# D1H register map
Vendor: Allwinner; File version: 1.0
Registers are 32-bit, read-write, reset 0x0 unless marked. A register's access mark holds for its fields unless they carry their own. Offsets are from the block's base; [hi:lo] are bit positions; {n}, {i} and the like mark numbered series.

## CIR_RX — Counsumer Infrared Receiver
Base 0x07040000
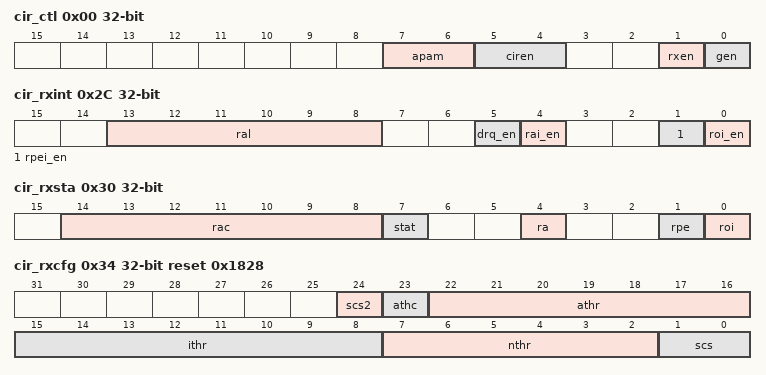
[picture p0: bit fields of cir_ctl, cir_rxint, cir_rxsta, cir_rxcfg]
0x00 cir_ctl — CIR Control Register
  [7:6] apam — Active Pulse Accept Mode
    0=BOTH_VALID (Both positive and negative pulses are valid as a leading code); 2=ONLY_NEGATIVE (Only negative pulse is valid as a leading code); 3=ONLY_POSITIVE (Only positive pulse is valid as a leading code)
  [5:4] ciren — CIR Enable
    3=ENABLE (CIR mode enable)
  [1] rxen — Receiver Block Enable
    0=DISABLE; 1=ENABLE
  [0] gen — Global Enable . A disable on this bit overrides any other block or channel enables and flushes all FIFOs.
    0=DISABLE; 1=ENABLE
0x10 cir_rxpcfg reset 0x4 — CIR Receiver Pulse Configure Register
  [2] rppi — Receiver Pulse Polarity Invert
    0=NOT_INVERT (Do not invert receiver signal); 1=INVERT (Invert receiver signal)
0x20 cir_rxfifo — CIR Receiver FIFO Register
  [7:0] rbf ro — Receiver Byte FIFO
0x2C cir_rxint — CIR Receiver Interrupt Control Register
  [13:8] ral — RX FIFO available received byte level for interrupt and DMA request . TRIGGER_LEVEL = RAL + 1
  [5] drq_en — RX FIFO DMA Enable
    0=DISABLE; 1=ENABLE
  [4] rai_en — RX FIFO Available Interrupt Enable
    0=DISABLE; 1=ENABLE
  [1] rpei_en — Receiver Packet End Interrupt Enable
    0=DISABLE; 1=ENABLE
  [0] roi_en — Receiver FIFO Overrun Interrupt Enable
    0=DISABLE; 1=ENABLE
0x30 cir_rxsta — CIR Receiver Status Register
  [14:8] rac ro — RX FIFO Available Counter
    0=B0 (No available data in RX FIFO); 1=B1 (1 byte available in RX FIFO); {v}=B{v} ({v} bytes available in RX FIFO) (v=2..64)
  [7] stat ro — Status of CIR
    0=IDLE; 1=BUSY
  [4] ra write-1-clears — RX FIFO Available
    0=NO_AVAILABLE (RX FIFO not available according to its level); 1=AVAILABLE (RX FIFO available according to its level Writing 1 clears this bit.)
  [1] rpe write-1-clears — Receiver Packet End Flag
    0=NOT_DETECTED (STO was not detected. In CIR mode, one CIR symbol is receiving or not detected.); 1=STO_FIELD (STO field or packet abort symbol (7'b0000,000 and 8'b0000,0000 for MIR and FIR) is detected. In CIR mode, one CIR symbol is received.)
  [0] roi write-1-clears — Receiver FIFO Overrun
    0=NOT_OVERRUN (Receiver FIFO not overrun); 1=OVERRUN (Receiver FIFO overrun)
0x34 cir_rxcfg reset 0x1828 — CIR Receiver Configure Register
  [24] scs2 — Bit2 of Sample Clock Select for CIR . This bit is defined by SCS bits below.
  [23] athc — Active Threshold Control for CIR
    0=SAMPLE (ATHR in a unit of (Sample Clock)); 1=SAMPLE_128 (ATHR in a unit of (128*Sample Clocks))
  [22:16] athr — Active Threshold for CIR . These bits control the duration of CIR from the idle to the active state. The duration can be calculated by ((ATHR + 1)*(ATHC? Sample Clock: 128*Sample Clock)).
  [15:8] ithr — Idle Threshold for CIR . The Receiver uses it to decide whether the CIR command is received. If there is no CIR signal on the air, the receiver is staying in IDLE status. One active pulse will bring the receiver from IDLE status to Receiving status. After the CIR receiver ends, the inputting signal will keep the specified level (high or low level) for a long time. The receiver can use this idle signal duration to decide that it has received the CIR command. The corresponding flag is asserted. If the corresponding interrupt is enabled, the interrupt line is asserted to the CPU. . When the duration of the signal keeps one status (high or low level) for the specified duration ((ITHR + 1)*128 sample_clk), this means that the previous CIR command is finished.
  [7:2] nthr — Noise Threshold for CIR . When the duration of the signal pulse (high or low level) is less than NTHR, the pulse is taken as noise and should be discarded by hardware.
    0=T0 (All samples are recorded into RX FIFO); 1=T1 (If the signal is only one sample duration, it is taken as noise and discarded.); {v}=T{v} (If the signal is less than {v} sample duration, it is taken as noise and discarded) (v=2..61)
  [1:0] scs — Sample Clock Select for CIR
